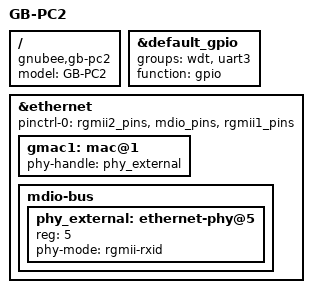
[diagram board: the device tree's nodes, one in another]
/dts-v1/;

#include "gbpc1.dts"

/ {
	compatible = "gnubee,gb-pc2", "mediatek,mt7621-soc";
	model = "GB-PC2";
};

&default_gpio {
	groups = "wdt", "uart3";
	function = "gpio";
};

&ethernet {
	pinctrl-0 = <&rgmii2_pins>, <&mdio_pins>, <&rgmii1_pins>;
	gmac1: mac@1 {
		status = "ok";
		phy-handle = <&phy_external>;
	};

	mdio-bus {
		phy_external: ethernet-phy@5 {
			reg = <5>;
			status = "ok";
			phy-mode = "rgmii-rxid";
		};
	};
};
